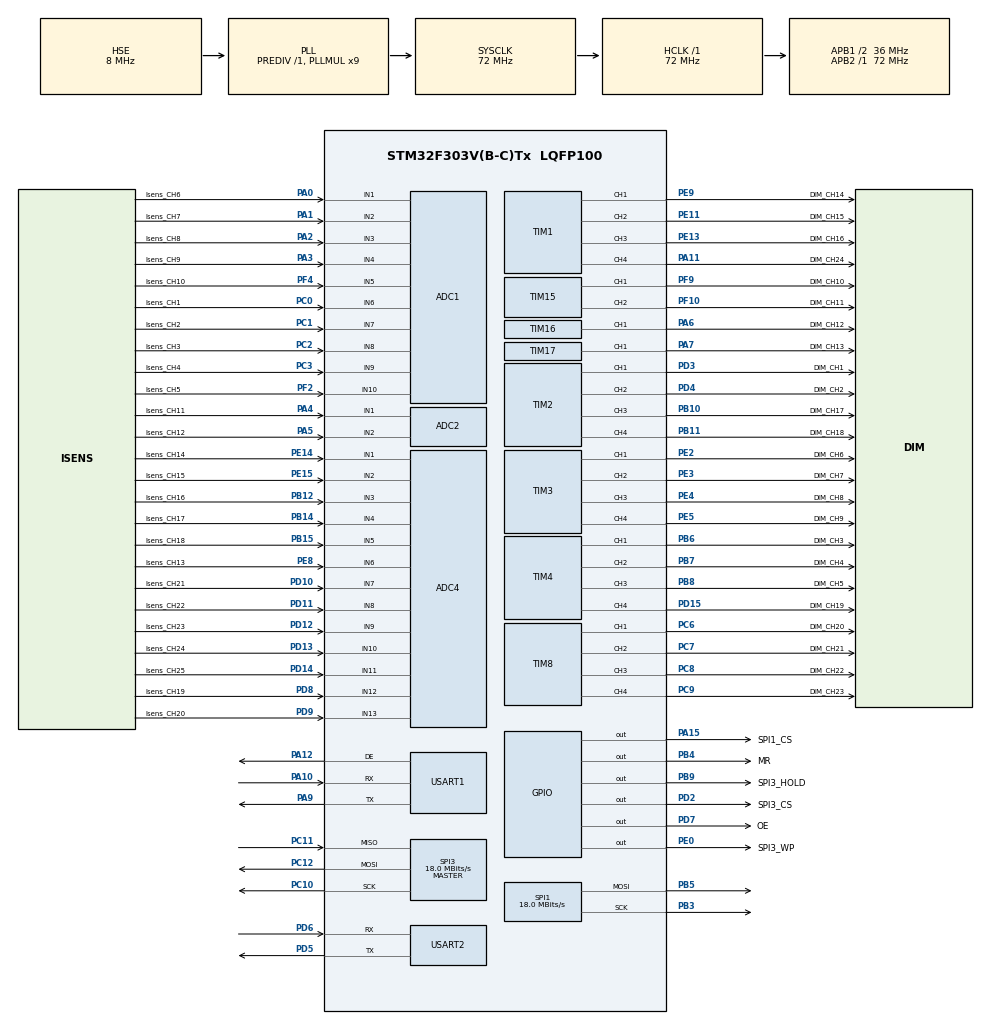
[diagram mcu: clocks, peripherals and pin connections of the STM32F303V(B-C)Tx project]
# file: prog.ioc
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ADC1.Channel-0\#ChannelRegularConversion=ADC_CHANNEL_1
ADC1.NbrOfConversionFlag=1
ADC1.Offset-0\#ChannelRegularConversion=0
ADC1.OffsetNumber-0\#ChannelRegularConversion=ADC_OFFSET_NONE
ADC1.Rank-0\#ChannelRegularConversion=1
ADC1.SamplingTime-0\#ChannelRegularConversion=ADC_SAMPLETIME_1CYCLE_5
ADC1.master=1
ADC2.Channel-2\#ChannelRegularConversion=ADC_CHANNEL_1
ADC2.NbrOfConversionFlag=1
ADC2.Offset-2\#ChannelRegularConversion=0
ADC2.OffsetNumber-2\#ChannelRegularConversion=ADC_OFFSET_NONE
ADC2.Rank-2\#ChannelRegularConversion=1
ADC2.SamplingTime-2\#ChannelRegularConversion=ADC_SAMPLETIME_1CYCLE_5
ADC4.Channel-0\#ChannelRegularConversion=ADC_CHANNEL_1
ADC4.NbrOfConversionFlag=1
ADC4.Offset-0\#ChannelRegularConversion=0
ADC4.OffsetNumber-0\#ChannelRegularConversion=ADC_OFFSET_NONE
ADC4.Rank-0\#ChannelRegularConversion=1
ADC4.SamplingTime-0\#ChannelRegularConversion=ADC_SAMPLETIME_1CYCLE_5
FREERTOS.Tasks01=MainTask,0,512,StartDefaultTask,Default,NULL,Dynamic,NULL,NULL;ModBus_Task,0,512,ModBusTask,Default,NULL,Dynamic,NULL,NULL
FREERTOS.configTOTAL_HEAP_SIZE=20480
Mcu.Family=STM32F3
Mcu.Name=STM32F303V(B-C)Tx
Mcu.Package=LQFP100
NVIC.PriorityGroup=NVIC_PRIORITYGROUP_4
NVIC.TIM7_IRQn=true\:0\:0\:false\:false\:true\:false\:false\:true
NVIC.TimeBase=TIM7_IRQn
NVIC.TimeBaseIP=TIM7
NVIC.USART1_IRQn=true\:5\:0\:false\:false\:true\:true\:true\:true
PA0.GPIO_Label=Isens_CH6
PA0.Mode=IN1-Single-Ended
PA0.Signal=ADC1_IN1
PA1.GPIO_Label=Isens_CH7
PA1.Mode=IN2-Single-Ended
PA1.Signal=ADC1_IN2
PA10.Mode=Asynchronous
PA10.Signal=USART1_RX
PA11.GPIO_Label=DIM_CH24
PA11.Signal=S_TIM1_CH4
PA12.Mode=Hardware Flow Control (RS485)
PA12.Signal=USART1_DE
PA13.Mode=Serial_Wire
PA13.Signal=SYS_JTMS-SWDIO
PA14.Mode=Serial_Wire
PA14.Signal=SYS_JTCK-SWCLK
PA15.GPIO_Label=SPI1_CS
PA15.Signal=GPIO_Output
PA2.GPIO_Label=Isens_CH8
PA2.Mode=IN3-Single-Ended
PA2.Signal=ADC1_IN3
PA3.GPIO_Label=Isens_CH9
PA3.Mode=IN4-Single-Ended
PA3.Signal=ADC1_IN4
PA4.GPIO_Label=Isens_CH11
PA4.Mode=IN1-Single-Ended
PA4.Signal=ADC2_IN1
PA5.GPIO_Label=Isens_CH12
PA5.Mode=IN2-Single-Ended
PA5.Signal=ADC2_IN2
PA6.GPIO_Label=DIM_CH12
PA6.Signal=S_TIM16_CH1
PA7.GPIO_Label=DIM_CH13
PA7.Signal=S_TIM17_CH1
PA9.Mode=Asynchronous
PA9.Signal=USART1_TX
PB10.GPIO_Label=DIM_CH17
PB10.Signal=S_TIM2_CH3
PB11.GPIO_Label=DIM_CH18
PB11.Signal=S_TIM2_CH4
PB12.GPIO_Label=Isens_CH16
PB12.Mode=IN3-Single-Ended
PB12.Signal=ADC4_IN3
PB14.GPIO_Label=Isens_CH17
PB14.Mode=IN4-Single-Ended
PB14.Signal=ADC4_IN4
PB15.GPIO_Label=Isens_CH18
PB15.Mode=IN5-Single-Ended
PB15.Signal=ADC4_IN5
PB3.Mode=TX_Only_Simplex_Unidirect_Master
PB3.Signal=SPI1_SCK
PB4.GPIO_Label=MR
PB4.Signal=GPIO_Output
PB5.Mode=TX_Only_Simplex_Unidirect_Master
PB5.Signal=SPI1_MOSI
PB6.GPIO_Label=DIM_CH3
PB6.Signal=S_TIM4_CH1
PB7.GPIO_Label=DIM_CH4
PB7.Signal=S_TIM4_CH2
PB8.GPIO_Label=DIM_CH5
PB8.Signal=S_TIM4_CH3
PB9.GPIO_Label=SPI3_HOLD
PB9.Signal=GPIO_Output
PC0.GPIO_Label=Isens_CH1
PC0.Signal=ADCx_IN6
PC1.GPIO_Label=Isens_CH2
PC1.Signal=ADCx_IN7
PC10.Mode=Full_Duplex_Master
PC10.Signal=SPI3_SCK
PC11.Mode=Full_Duplex_Master
PC11.Signal=SPI3_MISO
PC12.Mode=Full_Duplex_Master
PC12.Signal=SPI3_MOSI
PC2.GPIO_Label=Isens_CH3
PC2.Signal=ADCx_IN8
PC3.GPIO_Label=Isens_CH4
PC3.Signal=ADCx_IN9
PC6.GPIO_Label=DIM_CH20
PC6.Signal=S_TIM8_CH1
PC7.GPIO_Label=DIM_CH21
PC7.Signal=S_TIM8_CH2
PC8.GPIO_Label=DIM_CH22
PC8.Signal=S_TIM8_CH3
PC9.GPIO_Label=DIM_CH23
PC9.Signal=S_TIM8_CH4
PD10.GPIO_Label=Isens_CH21
PD10.Signal=ADCx_IN7P
PD11.GPIO_Label=Isens_CH22
PD11.Signal=ADCx_IN8P
PD12.GPIO_Label=Isens_CH23
PD12.Signal=ADCx_IN9P
PD13.GPIO_Label=Isens_CH24
PD13.Signal=ADCx_IN10P
PD14.GPIO_Label=Isens_CH25
PD14.Signal=ADCx_IN11
PD15.GPIO_Label=DIM_CH19
PD15.Signal=S_TIM4_CH4
PD2.GPIO_Label=SPI3_CS
PD2.Signal=GPIO_Output
PD3.GPIO_Label=DIM_CH1
PD3.Signal=S_TIM2_CH1_ETR
PD4.GPIO_Label=DIM_CH2
PD4.Signal=S_TIM2_CH2
PD5.Mode=Asynchronous
PD5.Signal=USART2_TX
PD6.Mode=Asynchronous
PD6.Signal=USART2_RX
PD7.GPIO_Label=OE
PD7.Signal=GPIO_Output
PD8.GPIO_Label=Isens_CH19
PD8.Mode=IN12-Single-Ended
PD8.Signal=ADC4_IN12
PD9.GPIO_Label=Isens_CH20
PD9.Mode=IN13-Single-Ended
PD9.Signal=ADC4_IN13
PE0.GPIO_Label=SPI3_WP
PE0.Signal=GPIO_Output
PE11.GPIO_Label=DIM_CH15
PE11.Signal=S_TIM1_CH2
PE13.GPIO_Label=DIM_CH16
PE13.Signal=S_TIM1_CH3
PE14.GPIO_Label=Isens_CH14
PE14.Mode=IN1-Single-Ended
PE14.Signal=ADC4_IN1
PE15.GPIO_Label=Isens_CH15
PE15.Mode=IN2-Single-Ended
PE15.Signal=ADC4_IN2
PE2.GPIO_Label=DIM_CH6
PE2.Signal=S_TIM3_CH1
PE3.GPIO_Label=DIM_CH7
PE3.Signal=S_TIM3_CH2
PE4.GPIO_Label=DIM_CH8
PE4.Signal=S_TIM3_CH3
PE5.GPIO_Label=DIM_CH9
PE5.Signal=S_TIM3_CH4
PE8.GPIO_Label=Isens_CH13
PE8.Signal=ADCx_IN6P
PE9.GPIO_Label=DIM_CH14
PE9.Signal=S_TIM1_CH1
PF0-OSC_IN.Mode=HSE-External-Oscillator
PF0-OSC_IN.Signal=RCC_OSC_IN
PF1-OSC_OUT.Mode=HSE-External-Oscillator
PF1-OSC_OUT.Signal=RCC_OSC_OUT
PF10.GPIO_Label=DIM_CH11
PF10.Signal=S_TIM15_CH2
PF2.GPIO_Label=Isens_CH5
PF2.Signal=ADCx_IN10
PF4.GPIO_Label=Isens_CH10
PF4.Mode=IN5-Single-Ended
PF4.Signal=ADC1_IN5
PF9.GPIO_Label=DIM_CH10
PF9.Signal=S_TIM15_CH1
ProjectManager.HeapSize=0x400
ProjectManager.StackSize=0x800
ProjectManager.TargetToolchain=EWARM V8.32
RCC.AHBFreq_Value=72000000
RCC.APB1CLKDivider=RCC_HCLK_DIV2
RCC.APB1Freq_Value=36000000
RCC.APB1TimFreq_Value=72000000
RCC.APB2Freq_Value=72000000
RCC.APB2TimFreq_Value=72000000
RCC.CortexFreq_Value=72000000
RCC.HCLKFreq_Value=72000000
RCC.HSE_VALUE=8000000
RCC.HSI_VALUE=8000000
RCC.LSE_VALUE=32768
RCC.PLLMUL=RCC_PLL_MUL9
RCC.PLLSourceVirtual=RCC_PLLSOURCE_HSE
RCC.SYSCLKFreq_VALUE=72000000
RCC.SYSCLKSourceVirtual=RCC_SYSCLKSOURCE_PLLCLK
RCC.USBFreq_Value=72000000
SH.ADCx_IN10.0=ADC1_IN10,IN10-Single-Ended
SH.ADCx_IN10P.0=ADC4_IN10,IN10-Single-Ended
SH.ADCx_IN11.0=ADC4_IN11,IN11-Single-Ended
SH.ADCx_IN6.0=ADC1_IN6,IN6-Single-Ended
SH.ADCx_IN6P.0=ADC4_IN6,IN6-Single-Ended
SH.ADCx_IN7.0=ADC1_IN7,IN7-Single-Ended
SH.ADCx_IN7P.0=ADC4_IN7,IN7-Single-Ended
SH.ADCx_IN8.0=ADC1_IN8,IN8-Single-Ended
SH.ADCx_IN8P.0=ADC4_IN8,IN8-Single-Ended
SH.ADCx_IN9.0=ADC1_IN9,IN9-Single-Ended
SH.ADCx_IN9P.0=ADC4_IN9,IN9-Single-Ended
SH.S_TIM15_CH1.0=TIM15_CH1,PWM Generation1 CH1
SH.S_TIM15_CH2.0=TIM15_CH2,PWM Generation2 CH2
SH.S_TIM16_CH1.0=TIM16_CH1,PWM Generation1 CH1
SH.S_TIM17_CH1.0=TIM17_CH1,PWM Generation1 CH1
SH.S_TIM1_CH1.0=TIM1_CH1,PWM Generation1 CH1
SH.S_TIM1_CH2.0=TIM1_CH2,PWM Generation2 CH2
SH.S_TIM1_CH3.0=TIM1_CH3,PWM Generation3 CH3
SH.S_TIM1_CH4.0=TIM1_CH4,PWM Generation4 CH4
SH.S_TIM2_CH1_ETR.0=TIM2_CH1,PWM Generation1 CH1
SH.S_TIM2_CH2.0=TIM2_CH2,PWM Generation2 CH2
SH.S_TIM2_CH3.0=TIM2_CH3,PWM Generation3 CH3
SH.S_TIM2_CH4.0=TIM2_CH4,PWM Generation4 CH4
SH.S_TIM3_CH1.0=TIM3_CH1,PWM Generation1 CH1
SH.S_TIM3_CH2.0=TIM3_CH2,PWM Generation2 CH2
SH.S_TIM3_CH3.0=TIM3_CH3,PWM Generation3 CH3
SH.S_TIM3_CH4.0=TIM3_CH4,PWM Generation4 CH4
SH.S_TIM4_CH1.0=TIM4_CH1,PWM Generation1 CH1
SH.S_TIM4_CH2.0=TIM4_CH2,PWM Generation2 CH2
SH.S_TIM4_CH3.0=TIM4_CH3,PWM Generation3 CH3
SH.S_TIM4_CH4.0=TIM4_CH4,PWM Generation4 CH4
SH.S_TIM8_CH1.0=TIM8_CH1,PWM Generation1 CH1
SH.S_TIM8_CH2.0=TIM8_CH2,PWM Generation2 CH2
SH.S_TIM8_CH3.0=TIM8_CH3,PWM Generation3 CH3
SH.S_TIM8_CH4.0=TIM8_CH4,PWM Generation4 CH4
SPI1.BaudRatePrescaler=SPI_BAUDRATEPRESCALER_4
SPI1.CalculateBaudRate=18.0 MBits/s
SPI1.Direction=SPI_DIRECTION_2LINES
SPI1.Mode=SPI_MODE_MASTER
SPI1.VirtualType=VM_MASTER
SPI3.CalculateBaudRate=18.0 MBits/s
SPI3.Direction=SPI_DIRECTION_2LINES
SPI3.Mode=SPI_MODE_MASTER
SPI3.VirtualType=VM_MASTER
TIM1.Channel-PWM\ Generation1\ CH1=TIM_CHANNEL_1
TIM1.Channel-PWM\ Generation2\ CH2=TIM_CHANNEL_2
TIM1.Channel-PWM\ Generation3\ CH3=TIM_CHANNEL_3
TIM1.Channel-PWM\ Generation4\ CH4=TIM_CHANNEL_4
TIM15.Channel-PWM\ Generation1\ CH1=TIM_CHANNEL_1
TIM15.Channel-PWM\ Generation2\ CH2=TIM_CHANNEL_2
TIM16.Channel=TIM_CHANNEL_1
TIM17.Channel=TIM_CHANNEL_1
TIM2.Channel-PWM\ Generation1\ CH1=TIM_CHANNEL_1
TIM2.Channel-PWM\ Generation2\ CH2=TIM_CHANNEL_2
TIM2.Channel-PWM\ Generation3\ CH3=TIM_CHANNEL_3
TIM2.Channel-PWM\ Generation4\ CH4=TIM_CHANNEL_4
TIM3.Channel-PWM\ Generation1\ CH1=TIM_CHANNEL_1
TIM3.Channel-PWM\ Generation2\ CH2=TIM_CHANNEL_2
TIM3.Channel-PWM\ Generation3\ CH3=TIM_CHANNEL_3
TIM3.Channel-PWM\ Generation4\ CH4=TIM_CHANNEL_4
TIM4.Channel-PWM\ Generation1\ CH1=TIM_CHANNEL_1
TIM4.Channel-PWM\ Generation2\ CH2=TIM_CHANNEL_2
TIM4.Channel-PWM\ Generation3\ CH3=TIM_CHANNEL_3
TIM4.Channel-PWM\ Generation4\ CH4=TIM_CHANNEL_4
TIM8.Channel-PWM\ Generation1\ CH1=TIM_CHANNEL_1
TIM8.Channel-PWM\ Generation2\ CH2=TIM_CHANNEL_2
TIM8.Channel-PWM\ Generation3\ CH3=TIM_CHANNEL_3
TIM8.Channel-PWM\ Generation4\ CH4=TIM_CHANNEL_4
USART1.VirtualMode-Asynchronous=VM_ASYNC
USART1.VirtualMode-Hardware\ Flow\ Control\ (RS485)=VM_ASYNC
USART2.VirtualMode-Asynchronous=VM_ASYNC
VP_FREERTOS_VS_CMSIS_V1.Mode=CMSIS_V1
VP_SYS_VS_tim7.Mode=TIM7
VP_TIM16_VS_ClockSourceINT.Mode=Enable_Timer
VP_TIM17_VS_ClockSourceINT.Mode=Enable_Timer
VP_TIM6_VS_ClockSourceINT.Mode=Enable_Timer
board=custom

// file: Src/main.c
/* USER CODE BEGIN Header */
/**
  ******************************************************************************
  * @file           : main.c
  * @brief          : Main program body
  ******************************************************************************
  * @attention
  *
  * <h2><center>&copy; Copyright (c) 2020 STMicroelectronics.
  * All rights reserved.</center></h2>
  *
  * This software component is licensed by ST under BSD 3-Clause license,
  * the "License"; You may not use this file except in compliance with the
  * License. You may obtain a copy of the License at:
  *                        opensource.org/licenses/BSD-3-Clause
  *
  ******************************************************************************
  */
/* USER CODE END Header */

#include "main.h"
#include "cmsis_os.h"
#include "adc.h"
#include "spi.h"
#include "tim.h"
#include "usart.h"
#include "gpio.h"

/* USER CODE BEGIN PV */
settings_t settings = {115200, 0x0D, 0};
bool resetSettings = false;
/* USER CODE END PV */

void SystemClock_Config(void);
void MX_FREERTOS_Init(void);

int main(void)
{

  /* MCU Configuration--------------------------------------------------------*/

  /* Reset of all peripherals, Initializes the Flash interface and the Systick. */
  HAL_Init();

  /* Configure the system clock */
  SystemClock_Config();

  /* Initialize all configured peripherals */
  MX_GPIO_Init();
  MX_ADC1_Init();
  MX_ADC4_Init();
  MX_TIM1_Init();
  MX_TIM2_Init();
  MX_TIM3_Init();
  MX_TIM4_Init();
  MX_TIM8_Init();
  MX_TIM6_Init();
  MX_USART1_UART_Init();
  MX_ADC2_Init();
  MX_SPI1_Init();
  MX_SPI3_Init();
  MX_TIM15_Init();
  MX_TIM16_Init();
  MX_TIM17_Init();
  MX_USART2_UART_Init();
  /* USER CODE BEGIN 2 */

  //Flash_ReadParams(&settings, StartSettingsAddres);

  if((settings.BaudRate == 0) | (settings.BaudRate == 0xFFFFFFFF) | resetSettings)
    {

      settings.BaudRate = 115200;
      settings.SlaveAddress = 0x0D;
      //FLASH_WriteSettings(settings, StartSettingsAddres);
    }
  /* USER CODE END 2 */

  /* Call init function for freertos objects (in freertos.c) */
  MX_FREERTOS_Init();
  /* Start scheduler */
  osKernelStart();

  /* We should never get here as control is now taken by the scheduler */
  /* Infinite loop */
  while (1)
  {

  }
}

void SystemClock_Config(void)
{
  RCC_OscInitTypeDef RCC_OscInitStruct = {0};
  RCC_ClkInitTypeDef RCC_ClkInitStruct = {0};
  RCC_PeriphCLKInitTypeDef PeriphClkInit = {0};

  /** Initializes the CPU, AHB and APB busses clocks
  */
  RCC_OscInitStruct.OscillatorType = RCC_OSCILLATORTYPE_HSE;
  RCC_OscInitStruct.HSEState = RCC_HSE_ON;
  RCC_OscInitStruct.HSEPredivValue = RCC_HSE_PREDIV_DIV1;
  RCC_OscInitStruct.HSIState = RCC_HSI_ON;
  RCC_OscInitStruct.PLL.PLLState = RCC_PLL_ON;
  RCC_OscInitStruct.PLL.PLLSource = RCC_PLLSOURCE_HSE;
  RCC_OscInitStruct.PLL.PLLMUL = RCC_PLL_MUL9;
  if (HAL_RCC_OscConfig(&RCC_OscInitStruct) != HAL_OK)
  {
    Error_Handler();
  }
  /** Initializes the CPU, AHB and APB busses clocks
  */
  RCC_ClkInitStruct.ClockType = RCC_CLOCKTYPE_HCLK|RCC_CLOCKTYPE_SYSCLK
                              |RCC_CLOCKTYPE_PCLK1|RCC_CLOCKTYPE_PCLK2;
  RCC_ClkInitStruct.SYSCLKSource = RCC_SYSCLKSOURCE_PLLCLK;
  RCC_ClkInitStruct.AHBCLKDivider = RCC_SYSCLK_DIV1;
  RCC_ClkInitStruct.APB1CLKDivider = RCC_HCLK_DIV2;
  RCC_ClkInitStruct.APB2CLKDivider = RCC_HCLK_DIV1;

  if (HAL_RCC_ClockConfig(&RCC_ClkInitStruct, FLASH_LATENCY_2) != HAL_OK)
  {
    Error_Handler();
  }
  PeriphClkInit.PeriphClockSelection = RCC_PERIPHCLK_USART1|RCC_PERIPHCLK_USART2
                              |RCC_PERIPHCLK_TIM1|RCC_PERIPHCLK_TIM8
                              |RCC_PERIPHCLK_ADC12|RCC_PERIPHCLK_ADC34;
  PeriphClkInit.Usart1ClockSelection = RCC_USART1CLKSOURCE_PCLK2;
  PeriphClkInit.Usart2ClockSelection = RCC_USART2CLKSOURCE_PCLK1;
  PeriphClkInit.Adc12ClockSelection = RCC_ADC12PLLCLK_DIV1;
  PeriphClkInit.Adc34ClockSelection = RCC_ADC34PLLCLK_DIV1;
  PeriphClkInit.Tim1ClockSelection = RCC_TIM1CLK_HCLK;
  PeriphClkInit.Tim8ClockSelection = RCC_TIM8CLK_HCLK;
  if (HAL_RCCEx_PeriphCLKConfig(&PeriphClkInit) != HAL_OK)
  {
    Error_Handler();
  }
}

 /**
  * @brief  Period elapsed callback in non blocking mode
  * @note   This function is called  when TIM7 interrupt took place, inside
  * HAL_TIM_IRQHandler(). It makes a direct call to HAL_IncTick() to increment
  * a global variable "uwTick" used as application time base.
  * @param  htim : TIM handle
  * @retval None
  */
void HAL_TIM_PeriodElapsedCallback(TIM_HandleTypeDef *htim)
{
  if (htim->Instance == TIM7) {
    HAL_IncTick();
  }
}

void Error_Handler(void)
{
}

/************************ (C) COPYRIGHT STMicroelectronics *****END OF FILE****/

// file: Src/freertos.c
/* USER CODE BEGIN Header */
/**
  ******************************************************************************
  * File Name          : freertos.c
  * Description        : Code for freertos applications
  ******************************************************************************
  * @attention
  *
  * <h2><center>&copy; Copyright (c) 2020 STMicroelectronics.
  * All rights reserved.</center></h2>
  *
  * This software component is licensed by ST under Ultimate Liberty license
  * SLA0044, the "License"; You may not use this file except in compliance with
  * the License. You may obtain a copy of the License at:
  *                             www.st.com/SLA0044
  *
  ******************************************************************************
  */
/* USER CODE END Header */

#include "FreeRTOS.h"
#include "task.h"
#include "main.h"
#include "cmsis_os.h"

/* USER CODE BEGIN Includes */
#include "mb.h"
#include "mbport.h"

using namespace std;
/* USER CODE END Includes */

/* USER CODE BEGIN Variables */
extern SPI_HandleTypeDef hspi3;
extern settings_t settings;

/* USER CODE END Variables */
osThreadId MainTaskHandle;
osThreadId ModBus_TaskHandle;

/* USER CODE BEGIN FunctionPrototypes */
//   extern "C"
/* USER CODE END FunctionPrototypes */

void StartDefaultTask(void const * argument);
void ModBusTask(void const * argument);

void MX_FREERTOS_Init(void); /* (MISRA C 2004 rule 8.1) */

/* GetIdleTaskMemory prototype (linked to static allocation support) */
extern "C" void vApplicationGetIdleTaskMemory( StaticTask_t **ppxIdleTaskTCBBuffer, StackType_t **ppxIdleTaskStackBuffer, uint32_t *pulIdleTaskStackSize );

/* USER CODE BEGIN GET_IDLE_TASK_MEMORY */
static StaticTask_t xIdleTaskTCBBuffer;
static StackType_t xIdleStack[configMINIMAL_STACK_SIZE];

void vApplicationGetIdleTaskMemory( StaticTask_t **ppxIdleTaskTCBBuffer, StackType_t **ppxIdleTaskStackBuffer, uint32_t *pulIdleTaskStackSize )
{
  *ppxIdleTaskTCBBuffer = &xIdleTaskTCBBuffer;
  *ppxIdleTaskStackBuffer = &xIdleStack[0];
  *pulIdleTaskStackSize = configMINIMAL_STACK_SIZE;
  /* place for user code */
}
/* USER CODE END GET_IDLE_TASK_MEMORY */

void MX_FREERTOS_Init(void) {

  /* Create the thread(s) */
  /* definition and creation of MainTask */
  osThreadDef(MainTask, StartDefaultTask, osPriorityNormal, 0, 512);
  MainTaskHandle = osThreadCreate(osThread(MainTask), NULL);

  /* definition and creation of ModBus_Task */
  osThreadDef(ModBus_Task, ModBusTask, osPriorityNormal, 0, 512);
  ModBus_TaskHandle = osThreadCreate(osThread(ModBus_Task), NULL);

}

void StartDefaultTask(void const * argument)
{
  /* USER CODE BEGIN StartDefaultTask */
  uint8_t TxBuff[10] = {0x05};
  uint8_t RxBuff[50] = {0};
  uint16_t Size = 1;
  HAL_StatusTypeDef StatusSPI2;
  /* Infinite loop */
  for(;;)
  {
    // тестирование флешки
    HAL_GPIO_WritePin(SPI3_CS_GPIO_Port, SPI3_CS_Pin, GPIO_PIN_RESET);
    StatusSPI2 = HAL_SPI_Transmit(&hspi3, TxBuff, 1, 100);
    HAL_Delay(100);
    StatusSPI2 = HAL_SPI_Receive(&hspi3, RxBuff, Size, 100);
    StatusSPI2 = StatusSPI2;
    HAL_GPIO_WritePin(SPI3_CS_GPIO_Port, SPI3_CS_Pin, GPIO_PIN_SET);
    osDelay(1);
  }
  /* USER CODE END StartDefaultTask */
}

void ModBusTask(void const * argument)
{
  /* USER CODE BEGIN ModBusTask */
   /* Infinite loop */
   eMBErrorCode eStatus = eMBInit( MB_RTU, settings.SlaveAddress, 3, settings.BaudRate, MB_PAR_NONE );
   eStatus = eMBEnable();
   //HAL_TIM_Base_Start_IT(&htim17);
   for(;;)
   {
      eMBPoll();
      //taskYIELD();
   }
  /* USER CODE END ModBusTask */
}

/* USER CODE BEGIN Application */
/*description https://www.freemodbus.org/api/group__modbus__registers.html*/
//0x04
eMBErrorCode
eMBRegInputCB( UCHAR * pucRegBuffer, USHORT usAddress, USHORT usNRegs )
{
   eMBErrorCode    eStatus = MB_ENOERR;

   return eStatus;
}
//0x03 0x06 0x10
eMBErrorCode
eMBRegHoldingCB( UCHAR * pucRegBuffer, USHORT usAddress, USHORT usNRegs, eMBRegisterMode eMode )
{
   //uint8_t CMD[5] = {0};
   volatile HAL_StatusTypeDef status;

   if(usAddress == 0 ){}
   else{usAddress--;}

   eMBErrorCode    eStatus = MB_ENOERR;

   return eStatus;
}

// 0x01 0x0f 0x05
eMBErrorCode
eMBRegCoilsCB( UCHAR * pucRegBuffer, USHORT usAddress, USHORT usNCoils, eMBRegisterMode eMode )
{
   return MB_ENOREG;
}
//0x02
eMBErrorCode
eMBRegDiscreteCB( UCHAR * pucRegBuffer, USHORT usAddress, USHORT usNDiscrete )
{
   return MB_ENOREG;
}
/* USER CODE END Application */

/************************ (C) COPYRIGHT STMicroelectronics *****END OF FILE****/
